# PCIE0_DAT register map
Vendor: Texas Instruments
Registers are 32-bit, read-write, reset 0x0 unless marked. A register's access mark holds for its fields unless they carry their own. Offsets are as the file gives them; [hi:lo] are bit positions; {n}, {i} and the like mark numbered series; 'fields as' and 'values as' point back to an identical list.

## PCIE0_DAT (part 6 of 6)
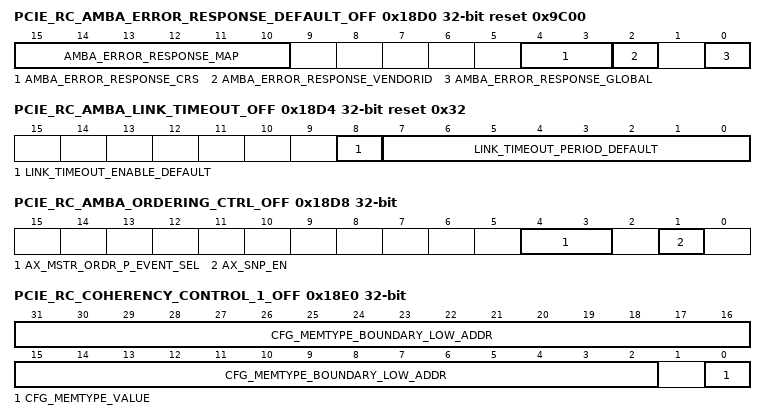
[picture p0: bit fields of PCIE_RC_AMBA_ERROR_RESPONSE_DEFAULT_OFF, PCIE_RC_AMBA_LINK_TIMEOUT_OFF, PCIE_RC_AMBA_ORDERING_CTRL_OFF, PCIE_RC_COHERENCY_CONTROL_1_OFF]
0x18D0 PCIE_RC_AMBA_ERROR_RESPONSE_DEFAULT_OFF access per field reset 0x9C00 — AXI Bridge Slave Error Response Register.
  [15:10] AMBA_ERROR_RESPONSE_MAP rw — AXI Slave Response Error Map Allows you to selectively map the errors received from the PCIe completion [for non-posted requests] to the AXI slave responses, slv_rresp or slv_bresp The recommended setting is SLVERR CRS is always mapped to OKAY - [0] -- 0: UR [unsupported request] -&gt; DECERR -- 1: UR [unsupported request] -&gt; SLVERR - [1] -- 0: CRS [configuration retry status] -&gt; DECERR -- 1: CRS [configuration retry status] -&gt; SLVERR - [2] -- 0: CA [completer abort] -&gt; DECERR -- 1: CA [completer abort] -&gt; SLVERR - [3]: Reserved - [4]: Reserved - [5]: -- 0: Completion Timeout -&gt; DECERR -- 1: Completion Timeout -&gt; SLVERR The AXI bridge internally drops [processes internally but not passed to your application] a completion that has been marked by the Rx filter as UC or MLF, and does not pass its status directly down to the slave interface It waits for a timeout and then signals 'Completion Timeout' to the slave interface The controller sets the AXI slave read databus to 0xFFFF for all error responses Note: This register field is sticky
  [4:3] AMBA_ERROR_RESPONSE_CRS rw — CRS Slave Error Response Mapping Determines the AXI slave response for CRS completions AHB: - always returns OKAY AXI: - 00: OKAY - 01: OKAY with all FFFF_FFFF data for all CRS completions - 10: OKAY with FFFF_0001 data for CRS completions to vendor ID read requests, OKAY with FFFF_FFFF data for all other CRS completions - 11: SLVERR/DECERR [the AXI_ERROR_RESPONSE_MAP field determines the PCIe-to-AXI Slave error response mapping] Note: This register field is sticky
  [2] AMBA_ERROR_RESPONSE_VENDORID rw — Vendor ID Non-existent Slave Error Response Mapping Determines the AXI slave response for errors on reads to non-existent Vendor ID register AHB: - 0: OKAY [with FFFF data] The controller ignores the setting in the bit when bit 0 of this register is '0' - 1: ERROR AXI: - 0: OKAY [with FFFF data] - 1: SLVERR/DECERR [the AXI_ERROR_RESPONSE_MAP field determines the PCIe-to-AXI Slave error response mapping] Note: This register field is sticky
  [0] AMBA_ERROR_RESPONSE_GLOBAL rw — Global Slave Error Response Mapping Determines the AXI slave response for all error scenarios on non-posted requests AHB: - 0: OKAY [with FFFF data for non-posted requests] and ignore the setting in bit [2] of this register - 1: ERROR for normal link [data] accesses and look at bit [2] for other scenarios AXI: - 0: OKAY [with FFFF data for non-posted requests] - 1: SLVERR/DECERR [the AXI_ERROR_RESPONSE_MAP field determines the PCIe-to-AXI Slave error response mapping] The error response mapping is not applicable to Non-existent Vendor ID register reads Note: This register field is sticky
0x18D4 PCIE_RC_AMBA_LINK_TIMEOUT_OFF access per field reset 0x32 — Link Down AXI Bridge Slave Timeout Register. If your application AXI master issues outbound requests to the AXI bridge slave interface before the PCIe link is operational, the controller starts a 'flush' timer. The timeout value of the timer is set by this register. The timer will timeout and then flush the bridge TX request queues after this amount of time. The timer counts when there are pending outbound AXI slave interface (or DMA) requests and the PCIe TX link is not transmitting any of these requests.
  [8] LINK_TIMEOUT_ENABLE_DEFAULT rw — Disable Flush You can disable the flush feature by setting this field to '1' Note: This register field is sticky
  [7:0] LINK_TIMEOUT_PERIOD_DEFAULT rw — Timeout Value [ms] The timer will timeout and then flush the bridge TX request queues after this amount of time The timer counts when there are pending outbound AXI slave interface requests and the PCIe TX link is not transmitting any of these requests The timer is clocked by core_clk For an M-PCIe configuration: - Time unit of this field is 4 ms - Margin of error for RateA clock is &lt; 1% - Margin of error for RateB clock is between 16% and 17% Note: This register field is sticky
0x18D8 PCIE_RC_AMBA_ORDERING_CTRL_OFF access per field — AMBA Ordering Control.
  [4:3] AX_MSTR_ORDR_P_EVENT_SEL rw — AXI Master Posted Ordering Event Selector This field selects how the master interface determines when a P write is completed when enforcing the PCIe ordering rule, 'NP must not pass P' at the AXI Master Interface The AXI protocol does not support ordering between channels Therefore, NP reads can pass P on your AXI bus fabric This can result in an ordering violation when the read overtakes a P that is going to the same address Therefore, the bridge master does not issue any NP requests until all outstanding P writes reach their destination It does this by waiting for the all of the write responses on the B channel This can affect the performance of the master read channel For scenarios where the interconnect serializes the AXI master 'AW', 'W' and 'AR' channels,you can increase the performance by reducing the need to wait until the complete Posted transaction has effectively reached the application slave - 00: B'last event: wait for the all of the write responses on the B channel thereby ensuring that the complete Posted transaction has effectively reached the application slave [default] - 01: AW'last event: wait until the complete Posted transaction has left the AXI address channel at the bridge master - 10: W'last event: wait until the complete Posted transaction has left the AXI data channel at the bridge master - 11: Reserved Note 2: This setting will not affect: - MSI interrupt catcher and P data ordering This is always driven by the B'last event - DMA read engine TLP ordering This is always driven by the B'last event - NP write transactions which are always serialized with P write transactions
  [1] AX_SNP_EN rw — AXI Serialize Non-Posted Requests Enable This field enables the AXI Bridge to serialize same ID Non-Posted Read/Write Requests on the wire Serialization implies one outstanding same ID NP Read or Write on the wire and used to avoid AXI RAR and WAW hazards at the remote link partner
0x18E0 PCIE_RC_COHERENCY_CONTROL_1_OFF access per field — ACE Cache Coherency Control Register 1
  [31:2] CFG_MEMTYPE_BOUNDARY_LOW_ADDR rw — Boundary Lower Address For Memory Type Bits [31:0] of dword-aligned address of the boundary for Memory type The two lower address LSBs are '00' Addresses up to but not including this value are in the lower address space region addresses equal or greater than this value are in the upper address space region Note: This register field is sticky
  [0] CFG_MEMTYPE_VALUE rw — Sets the memory type for the lower and upper parts of the address space: - 0: lower = Peripheral upper = Memory - 1: lower = Memory type upper = Peripheral Note: This register field is sticky
0x18E4 PCIE_RC_COHERENCY_CONTROL_2_OFF — ACE Cache Coherency Control Register 2
  [31:0] CFG_MEMTYPE_BOUNDARY_HIGH_ADDR — Boundary Upper Address For Memory Type Bits [63:32] of the 64-bit dword-aligned address of the boundary for Memory type Note: This register field is sticky
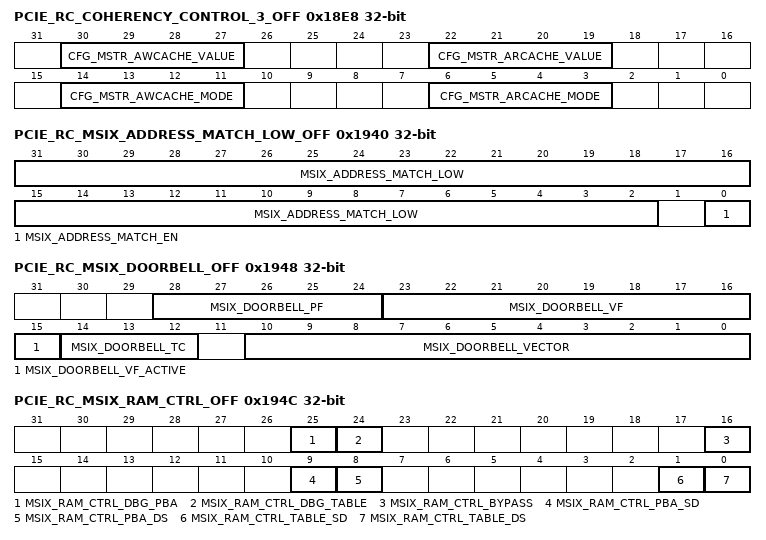
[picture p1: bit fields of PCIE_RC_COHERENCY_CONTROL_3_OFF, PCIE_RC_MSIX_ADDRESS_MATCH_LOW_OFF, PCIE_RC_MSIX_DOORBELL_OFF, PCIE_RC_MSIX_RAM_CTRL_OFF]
0x18E8 PCIE_RC_COHERENCY_CONTROL_3_OFF — ACE Cache Coherency Control Register 3
  [30:27] CFG_MSTR_AWCACHE_VALUE — Master Write CACHE Signal Value Value of the individual bits in mstr_awcache when CFG_MSTR_AWCACHE_MODE is '1' Note: not applicable to message requests for message requests the value of mstr_awcache is always '0000' Note: This register field is sticky
  [22:19] CFG_MSTR_ARCACHE_VALUE — Master Read CACHE Signal Value Value of the individual bits in mstr_arcache when CFG_MSTR_ARCACHE_MODE is '1' Note: This register field is sticky
  [14:11] CFG_MSTR_AWCACHE_MODE — Master Write CACHE Signal Behavior Defines how the individual bits in mstr_awcache are controlled: - 0: set automatically by the AXI master - 1: set by the value of the corresponding bit of the CFG_MSTR_AWCACHE_VALUE field Note: for message requests the value of mstr_awcache is always '0000' regardless of the value of this bit Note: This register field is sticky
  [6:3] CFG_MSTR_ARCACHE_MODE — Master Read CACHE Signal Behavior Defines how the individual bits in mstr_arcache are controlled: - 0: set automatically by the AXI master - 1: set by the value of the corresponding bit of the CFG_MSTR_ARCACHE_VALUE field Note: This register field is sticky
0x18F0 PCIE_RC_AXI_MSTR_MSG_ADDR_LOW_OFF access per field — Lower 20 bits of the programmable AXI address where Messages coming from wire are mapped to. Bits [11:0] of the register are tied to zero for the address to be 4k-aligned. In previous releases, the third and fourth DWORDs of a message (Msg/MsgD) TLP header were delivered though the AXI master address bus (mstr_awaddr). These DWORDS are now supplied through the mstr_awmisc_info_hdr_34dw[63:0] output; and the value on mstr_awaddr is driven to the value you have programmed into the and registers.
  [31:12] CFG_AXIMSTR_MSG_ADDR_LOW rw — Lower 20 bits of the programmable AXI address for Messages Note: This register field is sticky
0x18F4 PCIE_RC_AXI_MSTR_MSG_ADDR_HIGH_OFF — Upper 32 bits of the programmable AXI address where Messages coming from wire are mapped to.
  [31:0] CFG_AXIMSTR_MSG_ADDR_HIGH — Upper 32 bits of the programmable AXI address for Messages Note: This register field is sticky
0x18F8 PCIE_RC_PCIE_VERSION_NUMBER_OFF ro reset 0x3439302A — PCIe Controller IIP Release Version Number. The version number is given in hex format. You should convert each pair of hex characters to ASCII to interpret. Using 4.70a (GA) as an example: - VERSION_NUMBER = 0x3437302a which translates to 470* - VERSION_TYPE = 0x67612a2a which translates to ga** Using 4.70a-ea01 as an example: - VERSION_NUMBER = 0x3437302a which translates to 470* - VERSION_TYPE = 0x65613031 which translates to ea01 GA is a general release available on www.designware.com EA is an early release available on a per-customer basis.
  [31:0] VERSION_NUMBER
0x18FC PCIE_RC_PCIE_VERSION_TYPE_OFF ro reset not defined — PCIe Controller IIP Release Version Type. The type is given in hex format. You should convert each pair of hex characters to ASCII to interpret. Using 4.70a (GA) as an example: - VERSION_NUMBER = 0x3437302a which translates to 470* - VERSION_TYPE = 0x67612a2a which translates to ga** Using 4.70a-ea01 as an example: - VERSION_NUMBER = 0x3437302a which translates to 470* - VERSION_TYPE = 0x65613031 which translates to ea01 GA is a general release available on www.designware.com EA is an early release available on a per-customer basis.
  [31:0] VERSION_TYPE — Version Type SR2.0: 6C703039h SR1.0: 67612A2Ah
0x1940 PCIE_RC_MSIX_ADDRESS_MATCH_LOW_OFF access per field — MSI-X Address Match Low Register. When you enable the MSI-X Table RAM feature (MSIX_TABLE_EN=1), the controller implements the logic and RAM required to generate MSI-X requests. This register is only used in AXI configurations. When your local AXI application writes (MWr) to the address defined in this register (and ), the controller will load the register with the contents of the MWr and subsequently create and send MSI-X TLPs
  [31:2] MSIX_ADDRESS_MATCH_LOW rw — MSI-X Address Match Low Address Note: This register field is sticky
  [0] MSIX_ADDRESS_MATCH_EN rw — MSI-X Match Enable Enable the MSI-X Address Match feature when the AXI bridge is present Note: This register field is sticky
0x1944 PCIE_RC_MSIX_ADDRESS_MATCH_HIGH_OFF — MSI-X Address Match High Register. When you enable the MSI-X Table RAM feature (MSIX_TABLE_EN=1), the controller implements the logic and RAM required to generate MSI-X requests. This register is only used in AXI configurations. When your local AXI application writes (MWr) to the address defined in this register (and ), the controller will load the register with the contents of the MWr and subsequently create and send MSI-X TLPs
  [31:0] MSIX_ADDRESS_MATCH_HIGH — MSI-X Address Match High Address Note: This register field is sticky
0x1948 PCIE_RC_MSIX_DOORBELL_OFF — MSI-X Doorbell Register. When you enable the MSI-X Table RAM feature (MSIX_TABLE_EN=1), the controller implements the logic and RAM required to generate MSI-X requests. - For AXI configurations: when your local application writes (MWr) to the address defined in , the controller will load this register with the contents of the MWr and subsequently create and send MSI-X TLPs. - For AHB configurations: the MSI-X Table RAM feature is not supported. - For non-AMBA configurations: when your local application writes to this register, the controller will create and send MSI-X TLPs.
  [28:24] MSIX_DOORBELL_PF — MSIX Doorbell Physical Function This register determines the Physical Function for the MSI-X transaction
  [23:16] MSIX_DOORBELL_VF — MSIX Doorbell Virtual Function This register determines the Virtual Function for the MSI-X transaction
  [15] MSIX_DOORBELL_VF_ACTIVE — MSIX Doorbell Virtual Function Active This register determines whether a Virtual Function is used to generate the MSI-X transaction
  [14:12] MSIX_DOORBELL_TC — MSIX Doorbell Traffic Class This register determines which traffic class to generate the MSI-X transaction with
  [10:0] MSIX_DOORBELL_VECTOR — MSI-X Doorbell Vector This register determines which vector to generate the MSI-X transaction for
0x194C PCIE_RC_MSIX_RAM_CTRL_OFF access per field — MSI-X RAM power mode and debug control register. When you enable the MSI-X Table RAM feature (MSIX_TABLE_EN=1), the controller implements the logic and RAM required to generate MSI-X requests.
  [25] MSIX_RAM_CTRL_DBG_PBA rw — MSIX PBA RAM Debug Mode Use this bit to activate the debug mode and allow direct read/write access to the PBA Use can also use the dbg_pba input to activate debug mode Debug mode turns off the PF/VF/Offset-based addressing into the RAM and maps the entire table linearly from the base address of the BAR [indicated by the BIR] in function 0 Note: This register field is sticky
  [24] MSIX_RAM_CTRL_DBG_TABLE rw — MSIX Table RAM Debug Mode Use this bit to activate the debug mode and allow direct read/write access to the Table Use can also use the dbg_table input to activate debug mode Debug mode turns off the PF/VF/Offset-based addressing into the RAM and maps the entire table linearly from the base address of the BAR [indicated by the BIR] in function 0 Note: This register field is sticky
  [16] MSIX_RAM_CTRL_BYPASS rw — MSIX RAM Control Bypass The bypass field, when set, disables the internal generation of low power signals for both RAMs It is up to the application to ensure the RAMs are in the proper power state before trying to access them Moreover, the application needs to observe all timing requirements of the RAM low power signals before trying to use the MSIX functionality Note: This register field is sticky
  [9] MSIX_RAM_CTRL_PBA_SD rw — MSIX PBA RAM Shut Down Set this bit to drive the cfg_msix_pba_sd output to signal your external logic to place the MSIX PBA RAM in Shut Down low-power mode Note: This register field is sticky
  [8] MSIX_RAM_CTRL_PBA_DS rw — MSIX PBA RAM Deep Sleep Set this bit to drive the cfg_msix_pba_ds output to signal your external logic to place the MSIX PBA RAM in Deep Sleep low-power mode Note: This register field is sticky
  [1] MSIX_RAM_CTRL_TABLE_SD rw — MSIX Table RAM Shut Down Set this bit to drive the cfg_msix_table_sd output to signal your external logic to place the MSIX Table RAM in Shut Down low-power mode Note: This register field is sticky
  [0] MSIX_RAM_CTRL_TABLE_DS rw — MSIX Table RAM Deep Sleep Set this bit to drive the cfg_msix_table_ds output to signal your external logic to place the MSIX Table RAM in Deep Sleep low-power mode Note: This register field is sticky
0x1B40 PCIE_RC_AUX_CLK_FREQ_OFF access per field reset 0xA — Auxiliary Clock Frequency Control Register.
  [9:0] AUX_CLK_FREQ rw — The aux_clk frequency in MHz This value is used to provide a 1 us reference for counting time during low-power states with aux_clk when the PHY has removed the pipe_clk Frequencies lower than 1 MHz are possible but with a loss of accuracy in the time counted If the actual frequency [f] of aux_clk does not exactly match the programmed frequency [f_prog], then there is an error in the time counted by the controller that can be expressed in percentage as: err% = [f_prog/f-1]*100 For example if f=25 MHz and f_prog=3 MHz, then err% =[3/ 25-1]* 100 =20%, meaning that the time counted by the controller on aux_clk will be 20 0reater than the time in us programmed in the corresponding time register [for example T_POWER_ON] Note: This register field is sticky
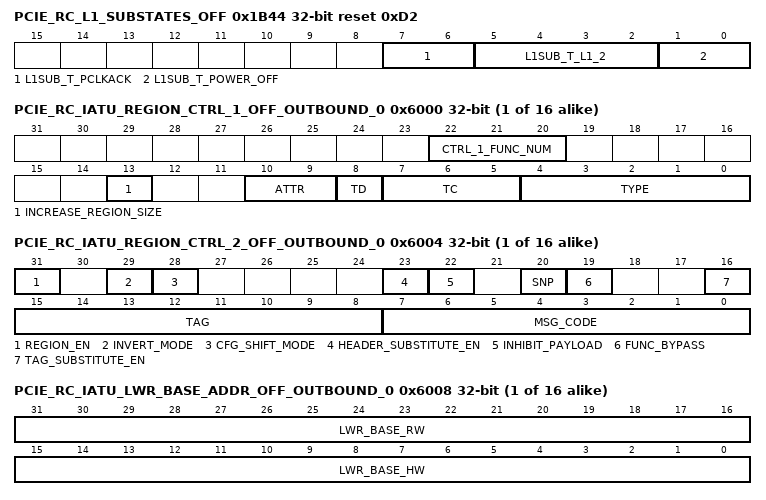
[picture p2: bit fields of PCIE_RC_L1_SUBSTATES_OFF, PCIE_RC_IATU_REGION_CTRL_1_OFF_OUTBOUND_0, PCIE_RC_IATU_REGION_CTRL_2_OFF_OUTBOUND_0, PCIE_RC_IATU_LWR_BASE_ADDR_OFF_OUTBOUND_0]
0x1B44 PCIE_RC_L1_SUBSTATES_OFF access per field reset 0xD2 — L1 Substates Timing Register.
  [7:6] L1SUB_T_PCLKACK rw — Max delay [in 1us units] between a MAC request to remove the clock on mac_phy_pclkreq_n and a PHY response on phy_mac_pclkack_n If the PHY does not respond within this time the request is aborted Range is 03 Note: This register field is sticky
  [5:2] L1SUB_T_L1_2 rw — Duration [in 1us units] of L12 Range is 015 Note: This register field is sticky
  [1:0] L1SUB_T_POWER_OFF rw — Duration [in 1us units] of L12Entry Range is 03 Note: This register field is sticky
{0x6000+0x200*i} PCIE_RC_IATU_REGION_CTRL_1_OFF_OUTBOUND_{i} (i=0..15) — iATU Region Control 1 Register.
  [22:20] CTRL_1_FUNC_NUM — Function Number - When the address of an outbound TLP is matched to this region and the FUNC_BYPASS field in the 'iATU Control 2 Register' is '0', then the function number used in generating the function part of the requester ID [RID] field of the TLP is taken from this 5-bit register The value in this register must be 0x0 unless multifunction operation in the controller is enabled [CX_NFUNC &gt; 1] - When you are using the AXI Bridge, then this field is swapped before AXI decomposition occurs so that the correct 'Max_Read_Request_Size' and 'Max_Payload_Size' values are used Note: This register field is sticky
  [13] INCREASE_REGION_SIZE — Increase the maximum ATU Region size When set, the maximum ATU Region size is determined by CX_ATU_MAX_REGION_SIZE When clear, the maximum ATU Region size is 4 GB [default] Note: This register field is sticky
  [10:9] ATTR — When the address of an outbound TLP is matched to this region, then the ATTR field of the TLP is changed to the value in this register Note: This register field is sticky
  [8] TD — When the address of an outbound TLP is matched to this region, then the TD field of the TLP is changed to the value in this register Note: This register field is sticky
  [7:5] TC — When the address of an outbound TLP is matched to this region, then the TC field of the TLP is changed to the value in this register Note: This register field is sticky
  [4:0] TYPE — When the address of an outbound TLP is matched to this region, then the TYPE field of the TLP is changed to the value in this register Note: This register field is sticky
{0x6004+0x200*i} PCIE_RC_IATU_REGION_CTRL_2_OFF_OUTBOUND_{i} (i=0..15) — iATU Region Control 2 Register.
  [31] REGION_EN — Region Enable This bit must be set to '1' for address translation to take place Note: This register field is sticky
  [29] INVERT_MODE — Invert Mode When set the address matching region is inverted Therefore, an address match occurs when the untranslated address is in the region outside the defined range [Base Address to Limit Address] Note: This register field is sticky
  [28] CFG_SHIFT_MODE — CFG Shift Mode The iATU uses bits [27:12] of the untranslated address [on the XALI0/1/2 interface or AXI slave interface address] to form the BDF number of the outgoing CFG TLP This supports the Enhanced Configuration Address Mapping [ECAM] mechanism [Section 722 of the PCI Express Base 31 Specification, revision 10] by allowing all outgoing I/O and MEM TLPs [that have been translated to CFG] to be mapped from memory space into any 256 MB region of the PCIe configuration space Note: This register field is sticky
  [23] HEADER_SUBSTITUTE_EN — Header Substitute Enable When enabled and region address is matched, the iATU fully substitutes bytes 8-11 [for 3 DWORD header] or bytes 12-15 [for 4 DWORD header] of the outbound TLP header with the contents of the LWR_TARGET_RW field in IATU_LWR_TARGET_ADDR_OFF_OUTBOUND_i - 1: LWR_TARGET_RW in the iATU_LWR_TARGET_ADDR_OFF_OUTBOUND_i register is used to fill bytes 8-to-11 [for 3 DWORD header] or bytes 12-to-15 [for 4 DWORD header] of the translated TLP header - 0: LWR_TARGET_RW in the iATU_LWR_TARGET_ADDR_OFF_OUTBOUND_i register forms the new address of the translated region Note: This register field is sticky
  [22] INHIBIT_PAYLOAD — Inhibit TLP Payload Data for TLP's in Matched Region assign iATU region to be TLP without data When enabled and region address is matched, the iATU marks all TLPs as having no payload data by forcing the TLP header Fmt[1] bit =0, regardless of the application inputs such as slv_wstrb - 1: Fmt[1] =0 so that only TLP type without data is sent For example, a Msg instead of MsgD will be sent - 0: Fmt[1] =0/1 so that TLPs with or without data can be sent Note: This register field is sticky
  [20] SNP — Serialize Non-Posted Requests In this mode, when the AXI Bridge is populated, same AXI ID Non-Posted Read/Write Requests are transmitted on the wire if there are no other same ID Non-Posted Requests outstanding Note: This register field is sticky
  [19] FUNC_BYPASS — Function Number Translation Bypass In this mode, the function number of the translated TLP is taken from your application transmit interface and not from the CTRL_1_FUNC_NUM field of the 'iATU Control 1 Register' or the VF_NUMBER field of the 'iATU Control 3 Register' Note: This register field is sticky
  [16] TAG_SUBSTITUTE_EN — TAG Substitute Enable When enabled and region address is matched, the iATU substitutes the TAG field of the outbound TLP header with the contents of the TAG field in this register The expected usage scenario is translation from AXI MWr to Vendor Defined Msg/MsgD Note [CX_TPH_ENABLE=1]: TAG substitution for MWr will not occur because this field [byte 6] in the TLP header is the ST field ST substitution can still take place using the MSG_CODE field in IATU_REGION_CTRL_2_OFF_OUTBOUND_i Note: This register field is sticky
  [15:8] TAG — TAG The substituted TAG field [byte 6] in the outgoing TLP header when TAG_SUBSTITUTE_EN is set Note: This register field is sticky
  [7:0] MSG_CODE — MSG TLPs [Message Code] When the address of an outbound TLP is matched to this region, and the translated TLP TYPE field is Msg or MsgD then the message field of the TLP is changed to the value in this register Memory TLPs: [ST Steering Tag] When the ST field of an outbound TLP is matched to this region, and the translated TLP TYPE field targets memory space then the ST field of the TLP is changed to the value in this register Only Valid when the CX_TPH_ENABLE configuration parameter is 1 Note: This register field is sticky
{0x6008+0x200*i} PCIE_RC_IATU_LWR_BASE_ADDR_OFF_OUTBOUND_{i} access per field (i=0..15) — iATU Lower Base Address Register. The CX_ATU_MIN_REGION_SIZE configuration parameter (Value Range: 4 kB, 8 kB, 16 kB, 32 kB, 64 kB defaults to 64 kB) specifies the minimum size of an address translation region. For example, if set to 64 kB; the lower 16 bits of the Base, Limit and Target registers are zero and all address regions are aligned on 64 kB boundaries. More precisely, the lower log2(CX_ATU_MIN_REGION_SIZE) bits are zero.
  [31:16] LWR_BASE_RW rw — Forms bits [31:n] of the start address of the address region to be translated n is log2[CX_ATU_MIN_REGION_SIZE] Note: This register field is sticky
  [15:0] LWR_BASE_HW ro — Forms bits [n- 1:0] of the start address of the address region to be translated The start address must be aligned to a CX_ATU_MIN_REGION_SIZE kB boundary, so these bits are always 0 A write to this location is ignored by the PCIe controller n is log2[CX_ATU_MIN_REGION_SIZE]
{0x600C+0x200*i} PCIE_RC_IATU_UPPER_BASE_ADDR_OFF_OUTBOUND_{i} (i=0..15) — iATU Upper Base Address Register.
  [31:0] UPPER_BASE_RW — Forms bits [63:32] of the start [and end] address of the address region to be translated In systems with a 32-bit address space, this register is not used and therefore writing to this register has no effect Note: This register field is sticky
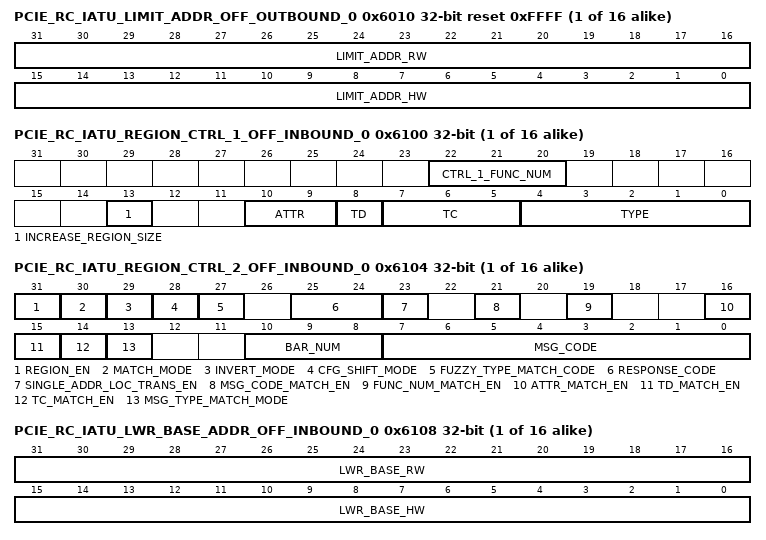
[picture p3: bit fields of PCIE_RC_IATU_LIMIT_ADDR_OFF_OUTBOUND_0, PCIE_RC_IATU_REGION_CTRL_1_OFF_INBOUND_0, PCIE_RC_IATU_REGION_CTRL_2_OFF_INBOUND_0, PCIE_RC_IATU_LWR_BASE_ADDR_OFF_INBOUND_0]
{0x6010+0x200*i} PCIE_RC_IATU_LIMIT_ADDR_OFF_OUTBOUND_{i} access per field reset 0xFFFF (i=0..15) — iATU Limit Address Register.
  [31:16] LIMIT_ADDR_RW rw — Forms upper bits of the end address of the address region to be translated The end address must be aligned to a CX_ATU_MIN_REGION_SIZE kB boundary, so these bits are always 0 A write to this location is ignored by the PCIe controller Note: This register field is sticky
  [15:0] LIMIT_ADDR_HW ro — Forms lower bits of the end address of the address region to be translated The end address must be aligned to a CX_ATU_MIN_REGION_SIZE kB boundary, so these bits are always 0 A write to this location is ignored by the PCIe controller
{0x6014+0x200*i} PCIE_RC_IATU_LWR_TARGET_ADDR_OFF_OUTBOUND_{i} (i=0..15) — iATU Lower Target Address Register.
  [31:0] LWR_TARGET_RW_OUTBOUND — When HEADER_SUBSTITUTE_EN in IATU_REGION_CTRL_2_OFF_OUTBOUND_ is '0' [normal operation]: - LWR_TARGET_RW[31:n] forms MSB's of the Lower Target part of the new address of the translated region - LWR_TARGET_RW[n-1:0] are not used [The start address must be aligned to a CX_ATU_MIN_REGION_SIZE kB boundary, so the lower bits of the start address of the new address of the translated region [bits n-1:0] are always '0'] - n is log2[CX_ATU_MIN_REGION_SIZE] When HEADER_SUBSTITUTE_EN in IATU_REGION_CTRL_2_OFF_OUTBOUND_i is '1': - LWR_TARGET_RW[31:0] forms bytes 8-11 [for 3 dword header] or bytes 12-15 [for 4 dword header] of the outbound TLP header Usage scenarios include the transmission of Vendor Defined Messages where the controller determines the content of bytes 12 to 15 of the TLP header Note: This register field is sticky
{0x6018+0x200*i} PCIE_RC_IATU_UPPER_TARGET_ADDR_OFF_OUTBOUND_{i} (i=0..15) — iATU Upper Target Address Register.
  [31:0] UPPER_TARGET_RW — Forms bits [63:32] of the start address [Upper Target part] of the new address of the translated region Note: This register field is sticky
{0x6100+0x200*i} PCIE_RC_IATU_REGION_CTRL_1_OFF_INBOUND_{i} (i=0..15) — iATU Region Control 1 Register.
  [22:20] CTRL_1_FUNC_NUM — Function Number - MEM-I/O: When the Address and BAR matching logic in the controller indicate that a MEM-I/O transaction matches a BAR in the function corresponding to this value, then address translation proceeds This check is only performed if the 'Function Number Match Enable' bit of the 'iATU Control 2 Register' is set - CFG0/CFG 1: When the destination function number as specified in the routing ID of the TLP header matches the function, then address translation proceeds This check is only performed if the 'Function Number Match Enable' bit of the 'iATU Control 2 Register' is set Note: This register field is sticky
  [13] INCREASE_REGION_SIZE — Increase the maximum ATU Region size When set, the maximum ATU Region size is determined by CX_ATU_MAX_REGION_SIZE When clear, the maximum ATU Region size is 4 GB [default] Note: This register field is sticky
  [10:9] ATTR — When the ATTR field of an inbound TLP is matched to this value, then address translation proceeds [when all other enabled field-matches are successful] This check is only performed if the 'ATTR Match Enable' bit of the 'iATU Control 2 Register' is set Note: This register field is sticky
  [8] TD — When the TD field of an inbound TLP is matched to this value, then address translation proceeds [when all other enabled field-matches are successful] This check is only performed if the 'TD Match Enable' bit of the 'iATU Control 2 Register' is set Note: This register field is sticky
  [7:5] TC — When the TC field of an inbound TLP is matched to this value, then address translation proceeds [when all other enabled field-matches are successful] This check is only performed if the 'TC Match Enable' bit of the 'iATU Control 2 Register' is set Note: This register field is sticky
  [4:0] TYPE — When the TYPE field of an inbound TLP is matched to this value, then address translation proceeds [when all other enabled field-matches are successful] Note: This register field is sticky
{0x6104+0x200*i} PCIE_RC_IATU_REGION_CTRL_2_OFF_INBOUND_{i} (i=0..15) — iATU Region Control 2 Register.
  [31] REGION_EN — Region Enable This bit must be set to '1' for address translation to take place Note: This register field is sticky
  [30] MATCH_MODE — Match Mode Determines Inbound matching mode for TLPs The mode depends on the type of TLP that is received as follows: For MEM-I/O TLPs, this field is interpreted as follows: - 0: Address Match Mode The iATU operates using addresses as in the outbound direction The Region Base and Limit Registers must be setup - 1:BAR Match Mode BAR matching is used The 'BAR Number' field is relevant Not used for RC For CFG0 TLPs, this field is interpreted as follows: - 0: Routing ID Match Mode The iATU interprets the Routing ID [Bytes 8 to 11 of TLP header] as an address This corresponds to the upper 16 bits of the address in MEM-I/O transactions The Routing ID of the TLP must be within the base and limit of the iATU region for matching to proceed - 1: Accept Mode The iATU accepts all CFG0 transactions as address matches The routing ID in the CFG0 TLP is ignored This is useful as all received CFG0 TLPs should be processed regardless of the Bus number For MSG/MSGD TLPs, this field is interpreted as follows: - 0: Address Match Mode The iATU treats the third dword and fourth dword of the inbound MSG/MSGD TLP as an address and it is matched against the Region Base and Limit Registers - 1: Vendor ID Match Mode This mode is relevant for ID-routed Vendor Defined Messages The iATU ignores the Routing ID [Bus, Device, Function] in bits [31:16] of the third dword of the TLP header, but matches against the Vendor ID in bits [15:0] of the third dword of the TLP header Bits [15:0] of the Region Upper Base register should be programmed with the required Vendor ID The lower Base and Limit Register should be programmed to translate TLPs based on vendor specific information in the fourth dword of the TLP header - If SINGLE_ADDRESS_LOCATION_TRANSLATE_EN = 1 AND MSG_TYPE_MATCH_MODE = 1, then Match Mode is ignored Note: This register field is sticky
  [29] INVERT_MODE — Invert Mode When set the address matching region is inverted Therefore, an address match occurs when the untranslated address is in the region outside the defined range [Base Address to Limit Address] Note: This register field is sticky
  [28] CFG_SHIFT_MODE — CFG Shift Mode This is useful for CFG transactions where the PCIe configuration mechanism maps bits [27:12] of the address to the bus/device and function number This allows a CFG configuration space to be located in any 256MB window of your application memory space using a 28-bit effective address Shifts bits [31:16] of the untranslated address to form bits [27:12] of the translated address Note: This register field is sticky
  [27] FUZZY_TYPE_MATCH_CODE — Fuzzy Type Match Mode When enabled, the iATU relaxes the matching of the TLP TYPE field against the expected TYPE field so that - CfgRd0 and CfgRd1 TLPs are seen as identical Similarly with CfgWr0 and CfgWr 1 - MWr, MRd and MRdLk TLPs are seen as identical - The Routing field of Msg/MsgD TLPs is ignored - FetchAdd, Swap and CAS are seen as identical For example, CFG0 in the TYPE field in the 'iATU Control 1 Register' matches against an inbound CfgRd0, CfgRd1, CfgWr0 or CfgWr1 TLP Note: This register field is sticky
  [25:24] RESPONSE_CODE — Response Code Defines the type of response to give for accesses matching this region This overrides the normal RADM filter response Note that this feature is not available for any region where Single Address Location Translate is enabled - 00 - Normal RADM filter response is used - 01 - Unsupported request [UR] - 10 - Completer abort [CA] - 11 - Not used / undefined / reserved Note: This register field is sticky
  [23] SINGLE_ADDR_LOC_TRANS_EN — Single Address Location Translate Enable When enabled, Rx TLPs can be translated to a single address location as determined by the target address register of the iATU region The main usage scenario is translation of Messages [such as Vendor Defined or ATS Messages] to MWr TLPs when the AXI bridge is enabled Note: This register field is sticky
  [21] MSG_CODE_MATCH_EN — Message Code Match Enable [Msg TLPS] Ensures that a successful message Code TLP field comparison match [see Message Code field of the 'iATU Control 2 Register'] occurs [in MSG transactions] for address translation to proceed ST Match Enable [Mem TLPs] Ensures that a successful ST TLP field comparison match [see ST field of the 'iATU Control 2 Register'] occurs [in MEM transactions] for address translation to proceed Only Valid when the CX_TPH_ENABLE configuration parameter is 1 Note: This register field is sticky
  [19] FUNC_NUM_MATCH_EN — Function Number Match Enable Ensures that a successful Function Number TLP field comparison match [see Function Number field of the 'iATU Control 1 Register'] occurs [in MEM-I/O and CFG0/CFG1 transactions] for address translation to proceed Note: This register field is sticky
  [16] ATTR_MATCH_EN — ATTR Match Enable Ensures that a successful ATTR TLP field comparison match [see ATTR field of the 'iATU Control 1 Register'] occurs for address translation to proceed Note: This register field is sticky
  [15] TD_MATCH_EN — TD Match Enable Ensures that a successful TD TLP field comparison match [see TD field of the 'iATU Control 1 Register'] occurs for address translation to proceed Note: This register field is sticky
  [14] TC_MATCH_EN — TC Match Enable Ensures that a successful TC TLP field comparison match [see TC field of the 'iATU Control 1 Register'] occurs for address translation to proceed Note: This register field is sticky
  [13] MSG_TYPE_MATCH_MODE — Message Type Match Mode When enabled, and if single address location translate enable is set, then inbound TLPs of type MSG/MSGd which match the type field of the iatu_region_ctrl_1_OFF_inbound register [=&gt;TYPE [4:3]=2'b10] will be translated Message type match mode overrides any value of MATCH_MODE field in this register Usage scenarios for this are translation of VDM or ATS messages when AXI bridge is configured on client interface Note: This register field is sticky
  [10:8] BAR_NUM — BAR Number When the BAR number of an inbound MEM or IO TLP ' that is matched by the normal internal BAR address matching mechanism ' is the same as this field, address translation proceeds [when all other enabled field-matches are successful] This check is only performed if the 'Match Mode' bit of the 'iATU Control 2 Register' is set - 000b - BAR 0 - 001b - BAR 1 - 010b - BAR 2 - 011b - BAR 3 - 100b - BAR 4 - 101b - BAR 5 - 110b - ROM - 111b - reserved - IO translation would require either 00100b or 00101b in the inbound TLP TYPE the BAR Number set in the range 000b - 101b and that BAR configured as an IO BAR Note: This register field is sticky
  [7:0] MSG_CODE — MSG TLPs: [Message Code] When the TYPE field of an inbound Msg/MsgD TLP is matched to this value, then address translation proceeds [when all other enabled field-matches are successful] This check is only performed if the 'Message Code Match Enable' bit of the 'iATU Control 2 Register' is set Memory TLPs: [ST Steering Tag] When the ST field of an inbound TLP is matched to this value, then address translation proceeds This check is only performed if the 'ST Match Enable' bit of the 'iATU Control2 Register' is set The setting is independent of the setting of the TH field Only Valid when the CX_TPH_ENABLE configuration parameter is 1 Note: This register field is sticky
{0x6108+0x200*i} PCIE_RC_IATU_LWR_BASE_ADDR_OFF_INBOUND_{i} access per field (i=0..15) — iATU Lower Base Address Register. The CX_ATU_MIN_REGION_SIZE configuration parameter (Value Range: 4 kB, 8 kB, 16 kB, 32 kB, 64 kB defaults to 64 kB) specifies the minimum size of an address translation region. For example, if set to 64 kB; the lower 16 bits of the Base, Limit and Target registers are zero and all address regions are aligned on 64 kB boundaries. More precisely, the lower log2(CX_ATU_MIN_REGION_SIZE) bits are zero.
  fields as PCIE_RC_IATU_LWR_BASE_ADDR_OFF_OUTBOUND_0
{0x610C+0x200*i} PCIE_RC_IATU_UPPER_BASE_ADDR_OFF_INBOUND_{i} (i=0..15) — iATU Upper Base Address Register.
  [31:0] UPPER_BASE_RW — Forms bits [63:32] of the start [and end] address of the address region to be translated Note: This register field is sticky
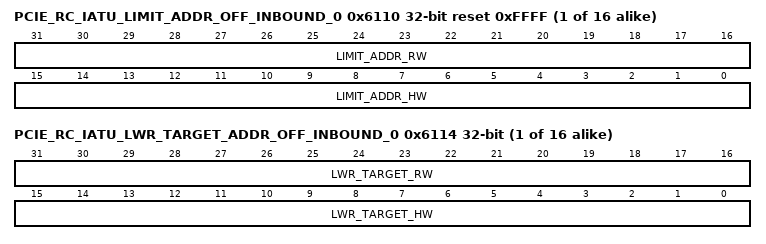
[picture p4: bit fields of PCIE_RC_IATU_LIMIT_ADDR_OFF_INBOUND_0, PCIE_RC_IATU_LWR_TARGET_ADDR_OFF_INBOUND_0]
{0x6110+0x200*i} PCIE_RC_IATU_LIMIT_ADDR_OFF_INBOUND_{i} access per field reset 0xFFFF (i=0..15) — iATU Limit Address Register.
  fields as PCIE_RC_IATU_LIMIT_ADDR_OFF_OUTBOUND_0
{0x6114+0x200*i} PCIE_RC_IATU_LWR_TARGET_ADDR_OFF_INBOUND_{i} access per field (i=0..15) — iATU Lower Target Address Register.
  [31:16] LWR_TARGET_RW rw — Forms MSB's of the Lower Target part of the new address of the translated region These bits are always '0' - Field size depends on log2[CX_ATU_MIN_REGION_SIZE] in address match mode - Field size depends on log2[BAR_MASK+1] in BAR match mode Note: This register field is sticky
  [15:0] LWR_TARGET_HW ro — Forms the LSB's of the Lower Target part of the new address of the translated region The start address must be aligned to a CX_ATU_MIN_REGION_SIZE kB boundary [in address match mode] and to the Bar size boundary [in BAR match mode] so that these bits are always '0' If the BAR is smaller than the iATU region size, then the iATU target address must align to the iATU region size otherwise it must align to the BAR size A write to this location is ignored by the PCIe controller - Field size depends on log2[CX_ATU_MIN_REGION_SIZE] in address match mode - Field size depends on log2[BAR_MASK+1] in BAR match mode
{0x6118+0x200*i} PCIE_RC_IATU_UPPER_TARGET_ADDR_OFF_INBOUND_{i} (i=0..15) — iATU Upper Target Address Register.
  [31:0] UPPER_TARGET_RW — Forms bits [63:32] of the start address [Upper Target part] of the new address of the translated region In systems with a 32-bit address space, this register is not used and therefore writing to this register has no effect Note: This register field is sticky
